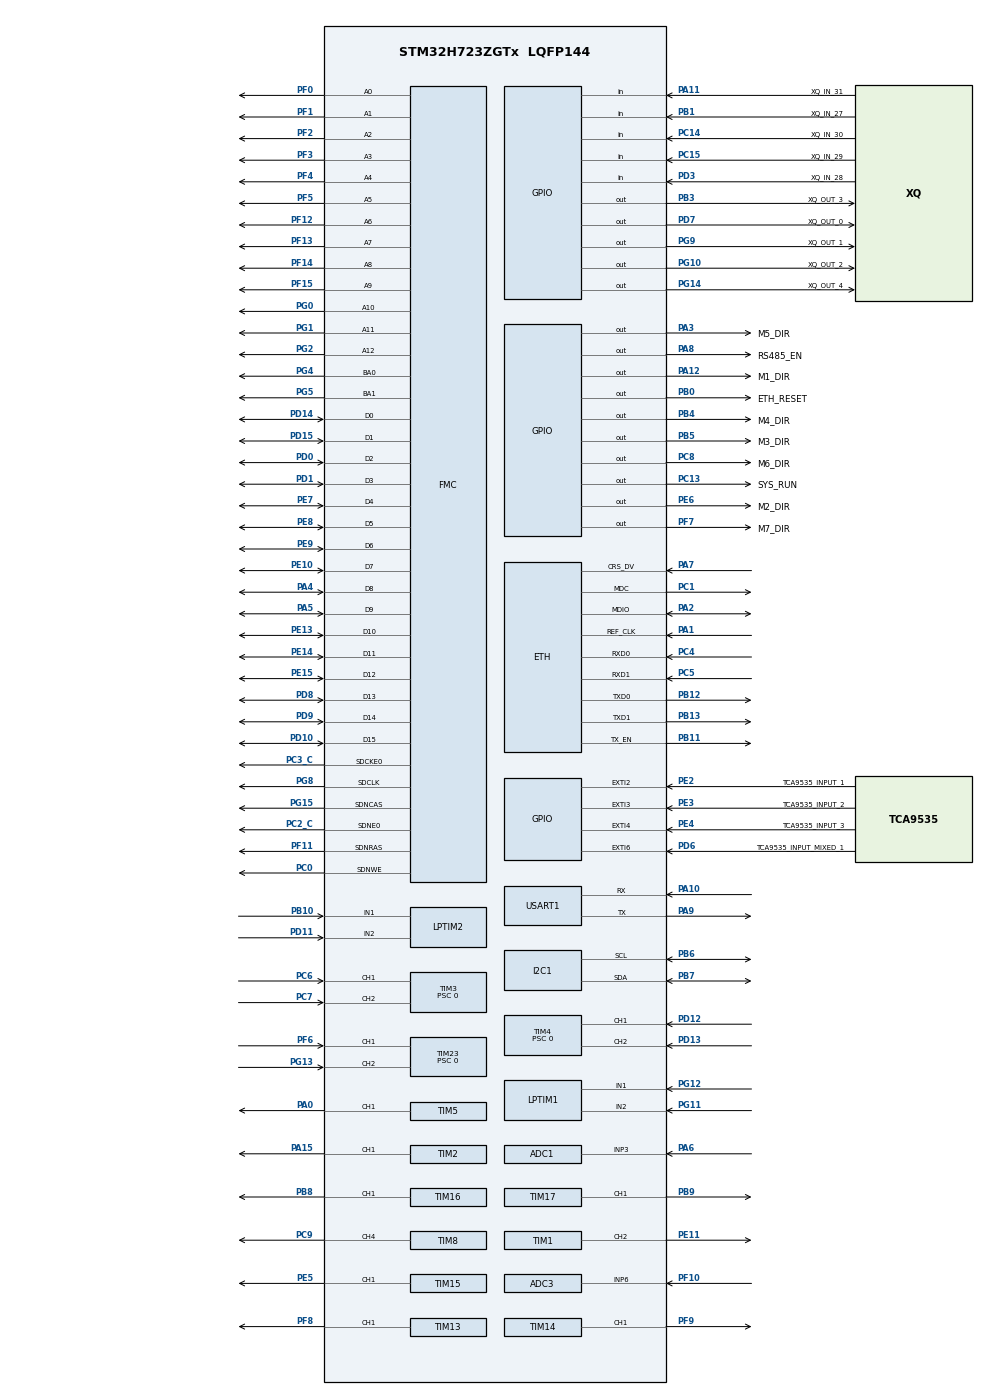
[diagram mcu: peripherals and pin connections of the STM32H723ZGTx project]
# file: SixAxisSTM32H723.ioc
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ADC1.Channel-1\#ChannelRegularConversion=ADC_CHANNEL_3
ADC1.ClockPrescaler=ADC_CLOCK_ASYNC_DIV2
ADC1.ClockPrescalerADC3=ADC_CLOCK_ASYNC_DIV2
ADC1.ContinuousConvMode=ENABLE
ADC1.ConversionDataManagement=ADC_CONVERSIONDATA_DMA_CIRCULAR
ADC1.DMAAccessModeView=ENABLE
ADC1.ExternalTrigConv=ADC_SOFTWARE_START
ADC1.Mode=ADC_DUALMODE_INTERL
ADC1.NbrOfConversion=1
ADC1.NbrOfConversionFlag=1
ADC1.OffsetNumber-1\#ChannelRegularConversion=ADC_OFFSET_NONE
ADC1.OffsetSignedSaturation-1\#ChannelRegularConversion=DISABLE
ADC1.Overrun=ADC_OVR_DATA_OVERWRITTEN
ADC1.Rank-1\#ChannelRegularConversion=1
ADC1.Resolution=ADC_RESOLUTION_14B
ADC1.SamplingTime-1\#ChannelRegularConversion=ADC_SAMPLETIME_2CYCLES_5
ADC1.TwoSamplingDelay=ADC_TWOSAMPLINGDELAY_2CYCLES
ADC1.master=1
ADC2.Channel-1\#ChannelRegularConversion=ADC_CHANNEL_3
ADC2.ClockPrescaler=ADC_CLOCK_ASYNC_DIV2
ADC2.ClockPrescalerADC3=ADC_CLOCK_ASYNC_DIV2
ADC2.DMAAccessModeView=ENABLE
ADC2.Mode=ADC_DUALMODE_INTERL
ADC2.NbrOfConversionFlag=1
ADC2.OffsetNumber-1\#ChannelRegularConversion=ADC_OFFSET_NONE
ADC2.OffsetSignedSaturation-1\#ChannelRegularConversion=DISABLE
ADC2.Rank-1\#ChannelRegularConversion=1
ADC2.Resolution=ADC_RESOLUTION_14B
ADC2.SamplingTime-1\#ChannelRegularConversion=ADC_SAMPLETIME_2CYCLES_5
ADC2.TwoSamplingDelay=ADC_TWOSAMPLINGDELAY_2CYCLES
ADC3.Channel-3\#ChannelRegularConversion=ADC_CHANNEL_6
ADC3.ClockPrescaler=ADC_CLOCK_ASYNC_DIV2
ADC3.ClockPrescalerADC3=ADC_CLOCK_ASYNC_DIV2
ADC3.ContinuousConvMode=DISABLE
ADC3.ConversionDataManagement=ADC_CONVERSIONDATA_DMA_CIRCULAR
ADC3.DMAAccessModeView=ENABLE
ADC3.DMAContinuousRequests=ENABLE
ADC3.ExternalTrigConv=ADC_EXTERNALTRIG_T6_TRGO
ADC3.Mode=ADC_DUALMODE_INTERL
ADC3.NbrOfConversion=1
ADC3.NbrOfConversionFlag=1
ADC3.OffsetNumber-3\#ChannelRegularConversion=ADC_OFFSET_NONE
ADC3.OffsetSign-3\#ChannelRegularConversion=ADC3_OFFSET_SIGN_NEGATIVE
ADC3.Overrun=ADC_OVR_DATA_OVERWRITTEN
ADC3.Rank-3\#ChannelRegularConversion=1
ADC3.SamplingTime-3\#ChannelRegularConversion=ADC3_SAMPLETIME_2CYCLES_5
ADC3.TwoSamplingDelay=ADC_TWOSAMPLINGDELAY_2CYCLES
CORTEX_M7.AccessPermission_S-Cortex_Memory_Protection_Unit_Region1_Settings_S=MPU_REGION_FULL_ACCESS
CORTEX_M7.AccessPermission_S-Cortex_Memory_Protection_Unit_Region2_Settings_S=MPU_REGION_FULL_ACCESS
CORTEX_M7.AccessPermission_S-Cortex_Memory_Protection_Unit_Region3_Settings_S=MPU_REGION_FULL_ACCESS
CORTEX_M7.AccessPermission_S-Cortex_Memory_Protection_Unit_Region4_Settings_S=MPU_REGION_FULL_ACCESS
CORTEX_M7.BaseAddress_S-Cortex_Memory_Protection_Unit_Region1_Settings_S=0x30000000
CORTEX_M7.BaseAddress_S-Cortex_Memory_Protection_Unit_Region2_Settings_S=0x30004000
CORTEX_M7.BaseAddress_S-Cortex_Memory_Protection_Unit_Region3_Settings_S=0x38000000
CORTEX_M7.BaseAddress_S-Cortex_Memory_Protection_Unit_Region4_Settings_S=0xC0000000
CORTEX_M7.CPU_DCache=Enabled
CORTEX_M7.CPU_ICache=Enabled
CORTEX_M7.DisableExec_S-Cortex_Memory_Protection_Unit_Region1_Settings_S=MPU_INSTRUCTION_ACCESS_DISABLE
CORTEX_M7.DisableExec_S-Cortex_Memory_Protection_Unit_Region2_Settings_S=MPU_INSTRUCTION_ACCESS_DISABLE
CORTEX_M7.DisableExec_S-Cortex_Memory_Protection_Unit_Region3_Settings_S=MPU_INSTRUCTION_ACCESS_ENABLE
CORTEX_M7.Enable_S-Cortex_Memory_Protection_Unit_Region1_Settings_S=MPU_REGION_ENABLE
CORTEX_M7.Enable_S-Cortex_Memory_Protection_Unit_Region2_Settings_S=MPU_REGION_ENABLE
CORTEX_M7.Enable_S-Cortex_Memory_Protection_Unit_Region3_Settings_S=MPU_REGION_ENABLE
CORTEX_M7.Enable_S-Cortex_Memory_Protection_Unit_Region4_Settings_S=MPU_REGION_ENABLE
CORTEX_M7.IsBufferable_S-Cortex_Memory_Protection_Unit_Region1_Settings_S=MPU_ACCESS_BUFFERABLE
CORTEX_M7.IsBufferable_S-Cortex_Memory_Protection_Unit_Region3_Settings_S=MPU_ACCESS_BUFFERABLE
CORTEX_M7.IsBufferable_S-Cortex_Memory_Protection_Unit_Region4_Settings_S=MPU_ACCESS_BUFFERABLE
CORTEX_M7.IsCacheable_S-Cortex_Memory_Protection_Unit_Region3_Settings_S=MPU_ACCESS_CACHEABLE
CORTEX_M7.IsCacheable_S-Cortex_Memory_Protection_Unit_Region4_Settings_S=MPU_ACCESS_CACHEABLE
CORTEX_M7.IsShareable_S-Cortex_Memory_Protection_Unit_Region3_Settings_S=MPU_ACCESS_SHAREABLE
CORTEX_M7.IsShareable_Spec=MPU_ACCESS_NOT_SHAREABLE
CORTEX_M7.Size_S-Cortex_Memory_Protection_Unit_Region1_Settings_S=MPU_REGION_SIZE_16KB
CORTEX_M7.Size_S-Cortex_Memory_Protection_Unit_Region2_Settings_S=MPU_REGION_SIZE_16KB
CORTEX_M7.Size_S-Cortex_Memory_Protection_Unit_Region3_Settings_S=MPU_REGION_SIZE_16KB
CORTEX_M7.Size_S-Cortex_Memory_Protection_Unit_Region4_Settings_S=MPU_REGION_SIZE_256MB
CORTEX_M7.TypeExtField_S-Cortex_Memory_Protection_Unit_Region1_Settings_S=MPU_TEX_LEVEL1
CORTEX_M7.TypeExtField_S-Cortex_Memory_Protection_Unit_Region2_Settings_S=MPU_TEX_LEVEL1
CORTEX_M7.TypeExtField_S-Cortex_Memory_Protection_Unit_Region3_Settings_S=MPU_TEX_LEVEL1
CORTEX_M7.default_mode_Activation=1
Dma.ADC1.0.Direction=DMA_PERIPH_TO_MEMORY
Dma.ADC1.0.EventEnable=DISABLE
Dma.ADC1.0.FIFOMode=DMA_FIFOMODE_DISABLE
Dma.ADC1.0.Instance=DMA1_Stream1
Dma.ADC1.0.MemDataAlignment=DMA_MDATAALIGN_WORD
Dma.ADC1.0.MemInc=DMA_MINC_ENABLE
Dma.ADC1.0.Mode=DMA_CIRCULAR
Dma.ADC1.0.PeriphDataAlignment=DMA_PDATAALIGN_WORD
Dma.ADC1.0.PeriphInc=DMA_PINC_DISABLE
Dma.ADC1.0.Polarity=HAL_DMAMUX_REQ_GEN_RISING
Dma.ADC1.0.Priority=DMA_PRIORITY_LOW
Dma.ADC1.0.RequestNumber=1
Dma.ADC1.0.SignalID=NONE
Dma.ADC1.0.SyncEnable=DISABLE
Dma.ADC1.0.SyncPolarity=HAL_DMAMUX_SYNC_NO_EVENT
Dma.ADC1.0.SyncRequestNumber=1
Dma.ADC1.0.SyncSignalID=NONE
Dma.ADC3.1.Direction=DMA_PERIPH_TO_MEMORY
Dma.ADC3.1.EventEnable=DISABLE
Dma.ADC3.1.FIFOMode=DMA_FIFOMODE_DISABLE
Dma.ADC3.1.Instance=DMA1_Stream2
Dma.ADC3.1.MemDataAlignment=DMA_MDATAALIGN_HALFWORD
Dma.ADC3.1.MemInc=DMA_MINC_ENABLE
Dma.ADC3.1.Mode=DMA_CIRCULAR
Dma.ADC3.1.PeriphDataAlignment=DMA_PDATAALIGN_HALFWORD
Dma.ADC3.1.PeriphInc=DMA_PINC_DISABLE
Dma.ADC3.1.Polarity=HAL_DMAMUX_REQ_GEN_RISING
Dma.ADC3.1.Priority=DMA_PRIORITY_LOW
Dma.ADC3.1.RequestNumber=1
Dma.ADC3.1.SignalID=NONE
Dma.ADC3.1.SyncEnable=DISABLE
Dma.ADC3.1.SyncPolarity=HAL_DMAMUX_SYNC_NO_EVENT
Dma.ADC3.1.SyncRequestNumber=1
Dma.ADC3.1.SyncSignalID=NONE
Dma.Request0=ADC1
Dma.Request1=ADC3
ETH.MediaInterface=HAL_ETH_RMII_MODE
FMC.CASLatency1=FMC_SDRAM_CAS_LATENCY_3
FMC.ColumnBitsNumber1=FMC_SDRAM_COLUMN_BITS_NUM_9
FMC.ExitSelfRefreshDelay1=8
FMC.LoadToActiveDelay1=3
FMC.RCDDelay1=2
FMC.RPDelay1=2
FMC.RPDelay2=2
FMC.ReadBurst1=FMC_SDRAM_RBURST_ENABLE
FMC.ReadBurst2=FMC_SDRAM_RBURST_ENABLE
FMC.ReadPipeDelay1=FMC_SDRAM_RPIPE_DELAY_1
FMC.ReadPipeDelay2=FMC_SDRAM_RPIPE_DELAY_1
FMC.RowCycleDelay1=7
FMC.RowCycleDelay2=7
FMC.SDClockPeriod1=FMC_SDRAM_CLOCK_PERIOD_2
FMC.SDClockPeriod2=FMC_SDRAM_CLOCK_PERIOD_2
FMC.SelfRefreshTime1=5
FMC.WriteRecoveryTime1=3
FREERTOS.Tasks01=defaultTask,24,512,StartDefaultTask,Default,NULL,Dynamic,NULL,NULL
FREERTOS.configQUEUE_REGISTRY_SIZE=32
FREERTOS.configTOTAL_HEAP_SIZE=131072
I2C1.Timing=0x20A0A3F6
LPTIM1.ULPClockPolarity=LPTIM_CLOCKPOLARITY_RISING_FALLING
LPTIM2.ULPClockPolarity=LPTIM_CLOCKPOLARITY_RISING_FALLING
LWIP.BSP.number=1
LWIP.GATEWAY_ADDRESS=192.168.010.001
LWIP.IP_ADDRESS=192.168.010.012
LWIP.LWIP_DHCP=0
LWIP.LWIP_SO_RCVTIMEO=1
LWIP.MEM_SIZE=15360
LWIP.NETMASK_ADDRESS=255.255.255.000
LWIP.Version=v2.2.1_Cube
LWIP0.BSP.STBoard=false
LWIP0.BSP.api=BSP_COMPONENT_DRIVER
LWIP0.BSP.component=LAN8742
LWIP0.BSP.instance=LAN8742
LWIP0.BSP.name=Driver_PHY
LWIP0.BSP.semaphore=S_LAN8742
LWIP0.BSP.solution=LAN8742
Mcu.Family=STM32H7
Mcu.Name=STM32H723ZGTx
Mcu.Package=LQFP144
NVIC.ADC3_IRQn=true\:5\:0\:false\:false\:true\:true\:true\:true\:true
NVIC.ADC_IRQn=true\:5\:0\:false\:false\:true\:true\:true\:true\:true
NVIC.DMA1_Stream1_IRQn=true\:5\:0\:false\:false\:true\:false\:false\:true\:true
NVIC.DMA1_Stream2_IRQn=true\:5\:0\:false\:false\:true\:false\:false\:true\:true
NVIC.ETH_IRQn=true\:5\:0\:false\:false\:true\:true\:true\:true\:true
NVIC.PriorityGroup=NVIC_PRIORITYGROUP_4
NVIC.TIM8_BRK_TIM12_IRQn=true\:15\:0\:false\:false\:true\:false\:false\:true\:true
NVIC.TimeBase=TIM8_BRK_TIM12_IRQn
NVIC.TimeBaseIP=TIM12
PA0.Signal=S_TIM5_CH1
PA1.GPIO_Speed=GPIO_SPEED_FREQ_VERY_HIGH
PA1.Mode=RMII
PA1.Signal=ETH_REF_CLK
PA10.Mode=Asynchronous
PA10.Signal=USART1_RX
PA11.GPIO_Label=XQ_IN_31
PA11.GPIO_PuPd=GPIO_PULLDOWN
PA11.Signal=GPIO_Input
PA12.GPIO_Label=M1_DIR
PA12.GPIO_Speed=GPIO_SPEED_FREQ_VERY_HIGH
PA12.Signal=GPIO_Output
PA15(JTDI).GPIO_PuPd=GPIO_PULLDOWN
PA15(JTDI).GPIO_Speed=GPIO_SPEED_FREQ_VERY_HIGH
PA15(JTDI).Signal=S_TIM2_CH1_ETR
PA2.GPIO_Speed=GPIO_SPEED_FREQ_VERY_HIGH
PA2.Mode=RMII
PA2.Signal=ETH_MDIO
PA3.GPIO_Label=M5_DIR
PA3.GPIO_Speed=GPIO_SPEED_FREQ_VERY_HIGH
PA3.Signal=GPIO_Output
PA4.Signal=FMC_D8_DA8
PA5.Signal=FMC_D9_DA9
PA6.Signal=ADCx_INP3
PA7.GPIO_Speed=GPIO_SPEED_FREQ_VERY_HIGH
PA7.Mode=RMII
PA7.Signal=ETH_CRS_DV
PA8.GPIO_Label=RS485_EN
PA8.GPIO_Speed=GPIO_SPEED_FREQ_VERY_HIGH
PA8.PinState=GPIO_PIN_SET
PA8.Signal=GPIO_Output
PA9.Mode=Asynchronous
PA9.Signal=USART1_TX
PB0.GPIO_Label=ETH_RESET
PB0.GPIO_Speed=GPIO_SPEED_FREQ_VERY_HIGH
PB0.PinState=GPIO_PIN_SET
PB0.Signal=GPIO_Output
PB1.GPIO_Label=XQ_IN_27
PB1.GPIO_PuPd=GPIO_PULLDOWN
PB1.Signal=GPIO_Input
PB10.Mode=Encoder_mode_occur1
PB10.Signal=LPTIM2_IN1
PB11.GPIO_Speed=GPIO_SPEED_FREQ_VERY_HIGH
PB11.Mode=RMII
PB11.Signal=ETH_TX_EN
PB12.GPIO_Speed=GPIO_SPEED_FREQ_VERY_HIGH
PB12.Mode=RMII
PB12.Signal=ETH_TXD0
PB13.GPIO_Speed=GPIO_SPEED_FREQ_VERY_HIGH
PB13.Mode=RMII
PB13.Signal=ETH_TXD1
PB3(JTDO/TRACESWO).GPIO_Label=XQ_OUT_3
PB3(JTDO/TRACESWO).PinState=GPIO_PIN_SET
PB3(JTDO/TRACESWO).Signal=GPIO_Output
PB4(NJTRST).GPIO_Label=M4_DIR
PB4(NJTRST).GPIO_Speed=GPIO_SPEED_FREQ_VERY_HIGH
PB4(NJTRST).Signal=GPIO_Output
PB5.GPIO_Label=M3_DIR
PB5.GPIO_Speed=GPIO_SPEED_FREQ_VERY_HIGH
PB5.Signal=GPIO_Output
PB6.Mode=I2C
PB6.Signal=I2C1_SCL
PB7.Mode=I2C
PB7.Signal=I2C1_SDA
PB8.GPIO_PuPd=GPIO_PULLDOWN
PB8.GPIO_Speed=GPIO_SPEED_FREQ_VERY_HIGH
PB8.Signal=S_TIM16_CH1
PB9.GPIO_PuPd=GPIO_PULLDOWN
PB9.GPIO_Speed=GPIO_SPEED_FREQ_VERY_HIGH
PB9.Signal=S_TIM17_CH1
PC0.Signal=FMC_SDNWE
PC1.GPIO_Speed=GPIO_SPEED_FREQ_VERY_HIGH
PC1.Mode=RMII
PC1.Signal=ETH_MDC
PC13.GPIO_Label=SYS_RUN
PC13.Signal=GPIO_Output
PC14-OSC32_IN.GPIO_Label=XQ_IN_30
PC14-OSC32_IN.GPIO_PuPd=GPIO_PULLDOWN
PC14-OSC32_IN.Signal=GPIO_Input
PC15-OSC32_OUT.GPIO_Label=XQ_IN_29
PC15-OSC32_OUT.GPIO_PuPd=GPIO_PULLDOWN
PC15-OSC32_OUT.Signal=GPIO_Input
PC2_C.Mode=SdramChipSelect1_1
PC2_C.Signal=FMC_SDNE0
PC3_C.Mode=SdramChipSelect1_1
PC3_C.Signal=FMC_SDCKE0
PC4.GPIO_Speed=GPIO_SPEED_FREQ_VERY_HIGH
PC4.Mode=RMII
PC4.Signal=ETH_RXD0
PC5.GPIO_Speed=GPIO_SPEED_FREQ_VERY_HIGH
PC5.Mode=RMII
PC5.Signal=ETH_RXD1
PC6.Signal=S_TIM3_CH1
PC7.Signal=S_TIM3_CH2
PC8.GPIO_Label=M6_DIR
PC8.GPIO_Speed=GPIO_SPEED_FREQ_VERY_HIGH
PC8.Signal=GPIO_Output
PC9.Signal=S_TIM8_CH4
PD0.Signal=FMC_D2_DA2
PD1.Signal=FMC_D3_DA3
PD10.Signal=FMC_D15_DA15
PD11.Mode=Encoder_mode_occur1
PD11.Signal=LPTIM2_IN2
PD12.GPIO_Speed=GPIO_SPEED_FREQ_VERY_HIGH
PD12.Signal=S_TIM4_CH1
PD13.GPIO_Speed=GPIO_SPEED_FREQ_VERY_HIGH
PD13.Signal=S_TIM4_CH2
PD14.Signal=FMC_D0_DA0
PD15.Signal=FMC_D1_DA1
PD3.GPIO_Label=XQ_IN_28
PD3.GPIO_PuPd=GPIO_PULLDOWN
PD3.Signal=GPIO_Input
PD6.GPIO_Label=TCA9535_INPUT_MIXED_1
PD6.GPIO_ModeDefaultEXTI=GPIO_MODE_IT_FALLING
PD6.Signal=GPXTI6
PD7.GPIO_Label=XQ_OUT_0
PD7.PinState=GPIO_PIN_SET
PD7.Signal=GPIO_Output
PD8.Signal=FMC_D13_DA13
PD9.Signal=FMC_D14_DA14
PE10.Signal=FMC_D7_DA7
PE11.Signal=S_TIM1_CH2
PE13.Signal=FMC_D10_DA10
PE14.Signal=FMC_D11_DA11
PE15.Signal=FMC_D12_DA12
PE2.GPIO_Label=TCA9535_INPUT_1
PE2.GPIO_ModeDefaultEXTI=GPIO_MODE_IT_FALLING
PE2.Signal=GPXTI2
PE3.GPIO_Label=TCA9535_INPUT_2
PE3.GPIO_ModeDefaultEXTI=GPIO_MODE_IT_FALLING
PE3.Signal=GPXTI3
PE4.GPIO_Label=TCA9535_INPUT_3
PE4.GPIO_ModeDefaultEXTI=GPIO_MODE_IT_FALLING
PE4.Signal=GPXTI4
PE5.GPIO_PuPd=GPIO_PULLDOWN
PE5.GPIO_Speed=GPIO_SPEED_FREQ_VERY_HIGH
PE5.Signal=S_TIM15_CH1
PE6.GPIO_Label=M2_DIR
PE6.GPIO_Speed=GPIO_SPEED_FREQ_VERY_HIGH
PE6.Signal=GPIO_Output
PE7.Signal=FMC_D4_DA4
PE8.Signal=FMC_D5_DA5
PE9.Signal=FMC_D6_DA6
PF0.Signal=FMC_A0
PF1.Signal=FMC_A1
PF10.Mode=IN6-Single-Ended
PF10.Signal=ADC3_INP6
PF11.Signal=FMC_SDNRAS
PF12.Signal=FMC_A6
PF13.Signal=FMC_A7
PF14.Signal=FMC_A8
PF15.Signal=FMC_A9
PF2.Signal=FMC_A2
PF3.Signal=FMC_A3
PF4.Signal=FMC_A4
PF5.Signal=FMC_A5
PF6.Mode=Encoder_Interface
PF6.Signal=TIM23_CH1
PF7.GPIO_Label=M7_DIR
PF7.GPIO_Speed=GPIO_SPEED_FREQ_VERY_HIGH
PF7.Signal=GPIO_Output
PF8.Signal=S_TIM13_CH1
PF9.Signal=S_TIM14_CH1
PG0.Signal=FMC_A10
PG1.Signal=FMC_A11
PG10.GPIO_Label=XQ_OUT_2
PG10.PinState=GPIO_PIN_SET
PG10.Signal=GPIO_Output
PG11.Mode=Encoder_mode_occur1
PG11.Signal=LPTIM1_IN2
PG12.Mode=Encoder_mode_occur1
PG12.Signal=LPTIM1_IN1
PG13.Signal=S_TIM23_CH2
PG14.GPIO_Label=XQ_OUT_4
PG14.PinState=GPIO_PIN_SET
PG14.Signal=GPIO_Output
PG15.Signal=FMC_SDNCAS
PG2.Signal=FMC_A12
PG4.Signal=FMC_A14_BA0
PG5.Signal=FMC_A15_BA1
PG8.Signal=FMC_SDCLK
PG9.GPIO_Label=XQ_OUT_1
PG9.PinState=GPIO_PIN_SET
PG9.Signal=GPIO_Output
PH0-OSC_IN.Mode=HSE-External-Oscillator
PH0-OSC_IN.Signal=RCC_OSC_IN
PH1-OSC_OUT.Mode=HSE-External-Oscillator
PH1-OSC_OUT.Signal=RCC_OSC_OUT
ProjectManager.HeapSize=0x200
ProjectManager.StackSize=0x400
ProjectManager.TargetToolchain=MDK-ARM V5.32
RCC.ADCFreq_Value=100000000
RCC.APB1Freq_Value=125000000
RCC.APB2Freq_Value=125000000
RCC.APB3Freq_Value=125000000
RCC.APB4Freq_Value=125000000
RCC.CortexFreq_Value=500000000
RCC.D1PPRE=RCC_APB3_DIV2
RCC.D2PPRE1=RCC_APB1_DIV2
RCC.D2PPRE2=RCC_APB2_DIV2
RCC.D3PPRE=RCC_APB4_DIV2
RCC.DIVM1=2
RCC.DIVM2=2
RCC.DIVN1=40
RCC.DIVN2=16
RCC.DIVP1=1
RCC.HCLKFreq_Value=250000000
RCC.HPRE=RCC_HCLK_DIV2
RCC.LPTIM1CLockSelection=RCC_LPTIM1CLKSOURCE_PLL2
RCC.LPTIM2CLockSelection=RCC_LPTIM2CLKSOURCE_PLL2
RCC.PLL2FRACN=0
RCC.PLL3_VCI_Range-AdvancedSettings=RCC_PLL3VCIRANGE_0
RCC.PLLFRACN=0
RCC.PLLSourceVirtual=RCC_PLLSOURCE_HSE
RCC.SYSCLKFreq_VALUE=500000000
RCC.SYSCLKSource=RCC_SYSCLKSOURCE_PLLCLK
RCC.USBFreq_Value=250000000
SH.ADCx_INP3.0=ADC1_INP3,IN3-Single-Ended
SH.ADCx_INP3.1=ADC2_INP3,IN3-Single-Ended
SH.FMC_A0.0=FMC_A0,13b-sda1
SH.FMC_A1.0=FMC_A1,13b-sda1
SH.FMC_A10.0=FMC_A10,13b-sda1
SH.FMC_A11.0=FMC_A11,13b-sda1
SH.FMC_A12.0=FMC_A12,13b-sda1
SH.FMC_A14_BA0.0=FMC_BA0,FourSdramBanks1
SH.FMC_A15_BA1.0=FMC_BA1,FourSdramBanks1
SH.FMC_A2.0=FMC_A2,13b-sda1
SH.FMC_A3.0=FMC_A3,13b-sda1
SH.FMC_A4.0=FMC_A4,13b-sda1
SH.FMC_A5.0=FMC_A5,13b-sda1
SH.FMC_A6.0=FMC_A6,13b-sda1
SH.FMC_A7.0=FMC_A7,13b-sda1
SH.FMC_A8.0=FMC_A8,13b-sda1
SH.FMC_A9.0=FMC_A9,13b-sda1
SH.FMC_D0_DA0.0=FMC_D0,sd-16b-d1
SH.FMC_D10_DA10.0=FMC_D10,sd-16b-d1
SH.FMC_D11_DA11.0=FMC_D11,sd-16b-d1
SH.FMC_D12_DA12.0=FMC_D12,sd-16b-d1
SH.FMC_D13_DA13.0=FMC_D13,sd-16b-d1
SH.FMC_D14_DA14.0=FMC_D14,sd-16b-d1
SH.FMC_D15_DA15.0=FMC_D15,sd-16b-d1
SH.FMC_D1_DA1.0=FMC_D1,sd-16b-d1
SH.FMC_D2_DA2.0=FMC_D2,sd-16b-d1
SH.FMC_D3_DA3.0=FMC_D3,sd-16b-d1
SH.FMC_D4_DA4.0=FMC_D4,sd-16b-d1
SH.FMC_D5_DA5.0=FMC_D5,sd-16b-d1
SH.FMC_D6_DA6.0=FMC_D6,sd-16b-d1
SH.FMC_D7_DA7.0=FMC_D7,sd-16b-d1
SH.FMC_D8_DA8.0=FMC_D8,sd-16b-d1
SH.FMC_D9_DA9.0=FMC_D9,sd-16b-d1
SH.FMC_SDCLK.0=FMC_SDCLK,13b-sda1
SH.FMC_SDNCAS.0=FMC_SDNCAS,13b-sda1
SH.FMC_SDNRAS.0=FMC_SDNRAS,13b-sda1
SH.FMC_SDNWE.0=FMC_SDNWE,13b-sda1
SH.S_TIM13_CH1.0=TIM13_CH1,PWM Generation1 CH1
SH.S_TIM14_CH1.0=TIM14_CH1,PWM Generation1 CH1
SH.S_TIM15_CH1.0=TIM15_CH1,PWM Generation1 CH1
SH.S_TIM16_CH1.0=TIM16_CH1,PWM Generation1 CH1
SH.S_TIM17_CH1.0=TIM17_CH1,PWM Generation1 CH1
SH.S_TIM1_CH2.0=TIM1_CH2,PWM Generation2 CH2
SH.S_TIM23_CH2.0=TIM23_CH2,Encoder_Interface
SH.S_TIM2_CH1_ETR.0=TIM2_CH1,PWM Generation1 CH1
SH.S_TIM3_CH1.0=TIM3_CH1,Encoder_Interface
SH.S_TIM3_CH2.0=TIM3_CH2,Encoder_Interface
SH.S_TIM4_CH1.0=TIM4_CH1,Encoder_Interface
SH.S_TIM4_CH2.0=TIM4_CH2,Encoder_Interface
SH.S_TIM5_CH1.0=TIM5_CH1,PWM Generation1 CH1
SH.S_TIM8_CH4.0=TIM8_CH4,PWM Generation4 CH4
TIM1.AutoReloadPreload=TIM_AUTORELOAD_PRELOAD_ENABLE
TIM1.Channel-PWM\ Generation2\ CH2=TIM_CHANNEL_2
TIM1.Prescaler=24
TIM13.AutoReloadPreload=TIM_AUTORELOAD_PRELOAD_ENABLE
TIM13.Channel=TIM_CHANNEL_1
TIM13.Prescaler=24
TIM14.AutoReloadPreload=TIM_AUTORELOAD_PRELOAD_ENABLE
TIM14.Channel=TIM_CHANNEL_1
TIM14.OCMode_PWM=TIM_OCMODE_PWM1
TIM14.Prescaler=24
TIM15.AutoReloadPreload=TIM_AUTORELOAD_PRELOAD_ENABLE
TIM15.Channel-PWM\ Generation1\ CH1=TIM_CHANNEL_1
TIM15.OCMode_PWM-PWM\ Generation1\ CH1=TIM_OCMODE_PWM1
TIM15.Prescaler=24
TIM16.AutoReloadPreload=TIM_AUTORELOAD_PRELOAD_ENABLE
TIM16.Channel=TIM_CHANNEL_1
TIM16.OCMode_PWM=TIM_OCMODE_PWM1
TIM16.Prescaler=24
TIM17.AutoReloadPreload=TIM_AUTORELOAD_PRELOAD_ENABLE
TIM17.Channel=TIM_CHANNEL_1
TIM17.OCMode_PWM=TIM_OCMODE_PWM1
TIM17.Prescaler=24
TIM2.AutoReloadPreload=TIM_AUTORELOAD_PRELOAD_ENABLE
TIM2.Channel-PWM\ Generation1\ CH1=TIM_CHANNEL_1
TIM2.OCMode_PWM-PWM\ Generation1\ CH1=TIM_OCMODE_PWM1
TIM2.Period=65535
TIM2.Prescaler=24
TIM2.Pulse-PWM\ Generation1\ CH1=500000
TIM23.AutoReloadPreload=TIM_AUTORELOAD_PRELOAD_ENABLE
TIM23.EncoderMode=TIM_ENCODERMODE_TI12
TIM23.Period=59999
TIM23.Prescaler=0
TIM3.AutoReloadPreload=TIM_AUTORELOAD_PRELOAD_ENABLE
TIM3.EncoderMode=TIM_ENCODERMODE_TI12
TIM3.Period=59999
TIM3.Prescaler=0
TIM4.AutoReloadPreload=TIM_AUTORELOAD_PRELOAD_ENABLE
TIM4.EncoderMode=TIM_ENCODERMODE_TI12
TIM4.IC1Filter=0
TIM4.IC2Filter=0
TIM4.Period=59999
TIM4.Prescaler=0
TIM5.AutoReloadPreload=TIM_AUTORELOAD_PRELOAD_ENABLE
TIM5.Channel-PWM\ Generation1\ CH1=TIM_CHANNEL_1
TIM5.Prescaler=24
TIM6.AutoReloadPreload=TIM_AUTORELOAD_PRELOAD_ENABLE
TIM6.Period=99
TIM6.Prescaler=0
TIM6.TIM_MasterOutputTrigger=TIM_TRGO_UPDATE
TIM7.AutoReloadPreload=TIM_AUTORELOAD_PRELOAD_ENABLE
TIM7.Prescaler=24
TIM8.AutoReloadPreload=TIM_AUTORELOAD_PRELOAD_ENABLE
TIM8.Channel-PWM\ Generation4\ CH4=TIM_CHANNEL_4
TIM8.OCMode_PWM-PWM\ Generation4\ CH4=TIM_OCMODE_PWM1
TIM8.Prescaler=24
USART1.VirtualMode-Asynchronous=VM_ASYNC
VP_FREERTOS_VS_CMSIS_V2.Mode=CMSIS_V2
VP_LWIP_VS_Enabled.Mode=Enabled
VP_MEMORYMAP_VS_MEMORYMAP.Mode=CurAppReg
VP_SYS_VS_tim12.Mode=TIM12
VP_TIM13_VS_ClockSourceINT.Mode=Enable_Timer
VP_TIM14_VS_ClockSourceINT.Mode=Enable_Timer
VP_TIM15_VS_ClockSourceINT.Mode=Internal
VP_TIM16_VS_ClockSourceINT.Mode=Enable_Timer
VP_TIM17_VS_ClockSourceINT.Mode=Enable_Timer
VP_TIM1_VS_ClockSourceINT.Mode=Internal
VP_TIM2_VS_ClockSourceINT.Mode=Internal
VP_TIM5_VS_ClockSourceINT.Mode=Internal
VP_TIM6_VS_ClockSourceINT.Mode=Enable_Timer
VP_TIM7_VS_ClockSourceINT.Mode=Enable_Timer
VP_TIM8_VS_ClockSourceINT.Mode=Internal
board=custom

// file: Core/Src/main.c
/* USER CODE BEGIN Header */
/**
  ******************************************************************************
  * @file           : main.c
  * @brief          : Main program body
  ******************************************************************************
  * @attention
  *
  * Copyright (c) 2025 STMicroelectronics.
  * All rights reserved.
  *
  * This software is licensed under terms that can be found in the LICENSE file
  * in the root directory of this software component.
  * If no LICENSE file comes with this software, it is provided AS-IS.
  *
  ******************************************************************************
  */
/* USER CODE END Header */
#include "main.h"
#include "FreeRTOS.h"
#include "cmsis_os2.h"
#include "adc.h"
#include "dma.h"
#include "i2c.h"
#include "lptim.h"
#include "lwip.h"
#include "tim.h"
#include "usart.h"
#include "gpio.h"
#include "fmc.h"

/* USER CODE BEGIN Includes */
#include "xq_axis.h"
#include "xq_io.h"
#include "xq_encoder.h"
#include "xq_pwm.h"
#include "mb.h"
/* USER CODE END Includes */

void SystemClock_Config(void);
void PeriphCommonClock_Config(void);
static void MPU_Config(void);
void MX_FREERTOS_Init(void);

/* USER CODE BEGIN 0 */

uint32_t data_len = 512;
uint32_t dmabuffer[512];

/* USER CODE END 0 */

int main(void)
{

  /* MPU Configuration--------------------------------------------------------*/
  MPU_Config();

  /* Enable the CPU Cache */

  /* Enable I-Cache---------------------------------------------------------*/
  SCB_EnableICache();

  /* Enable D-Cache---------------------------------------------------------*/
  SCB_EnableDCache();

  /* MCU Configuration--------------------------------------------------------*/

  /* Reset of all peripherals, Initializes the Flash interface and the Systick. */
  HAL_Init();

  /* USER CODE BEGIN Init */

  // SCB->CACR|=1<<2;

  /* USER CODE END Init */

  /* Configure the system clock */
  SystemClock_Config();

  /* Configure the peripherals common clocks */
  PeriphCommonClock_Config();

  /* Initialize all configured peripherals */
  MX_GPIO_Init();
  MX_DMA_Init();
  MX_TIM2_Init();
  MX_TIM8_Init();
  MX_TIM14_Init();
  MX_TIM15_Init();
  MX_TIM16_Init();
  MX_TIM17_Init();
  MX_TIM23_Init();
  MX_LPTIM2_Init();
  MX_TIM3_Init();
  MX_TIM4_Init();
  MX_I2C1_Init();
  MX_TIM1_Init();
  MX_TIM5_Init();
  MX_ADC1_Init();
  MX_ADC3_Init();
  MX_TIM7_Init();
  MX_USART1_UART_Init();
  MX_TIM6_Init();
  MX_TIM13_Init();
  MX_LPTIM1_Init();
  MX_FMC_Init();
  MX_ADC2_Init();
  /* USER CODE BEGIN 2 */

  printf ("System initialized.\n");

  /* USER CODE END 2 */

  /* Init scheduler */
  osKernelInitialize();  /* Call init function for freertos objects (in cmsis_os2.c) */
  MX_FREERTOS_Init();

  /* Start scheduler */
  osKernelStart();

  /* We should never get here as control is now taken by the scheduler */

  /* Infinite loop */
  while (1)
  {

  }
}

void SystemClock_Config(void)
{
  RCC_OscInitTypeDef RCC_OscInitStruct = {0};
  RCC_ClkInitTypeDef RCC_ClkInitStruct = {0};

  /** Supply configuration update enable
  */
  HAL_PWREx_ConfigSupply(PWR_LDO_SUPPLY);

  /** Configure the main internal regulator output voltage
  */
  __HAL_PWR_VOLTAGESCALING_CONFIG(PWR_REGULATOR_VOLTAGE_SCALE0);

  while(!__HAL_PWR_GET_FLAG(PWR_FLAG_VOSRDY)) {}

  /** Initializes the RCC Oscillators according to the specified parameters
  * in the RCC_OscInitTypeDef structure.
  */
  RCC_OscInitStruct.OscillatorType = RCC_OSCILLATORTYPE_HSE;
  RCC_OscInitStruct.HSEState = RCC_HSE_ON;
  RCC_OscInitStruct.PLL.PLLState = RCC_PLL_ON;
  RCC_OscInitStruct.PLL.PLLSource = RCC_PLLSOURCE_HSE;
  RCC_OscInitStruct.PLL.PLLM = 2;
  RCC_OscInitStruct.PLL.PLLN = 40;
  RCC_OscInitStruct.PLL.PLLP = 1;
  RCC_OscInitStruct.PLL.PLLQ = 2;
  RCC_OscInitStruct.PLL.PLLR = 2;
  RCC_OscInitStruct.PLL.PLLRGE = RCC_PLL1VCIRANGE_3;
  RCC_OscInitStruct.PLL.PLLVCOSEL = RCC_PLL1VCOWIDE;
  RCC_OscInitStruct.PLL.PLLFRACN = 0;
  if (HAL_RCC_OscConfig(&RCC_OscInitStruct) != HAL_OK)
  {
    Error_Handler();
  }

  /** Initializes the CPU, AHB and APB buses clocks
  */
  RCC_ClkInitStruct.ClockType = RCC_CLOCKTYPE_HCLK|RCC_CLOCKTYPE_SYSCLK
                              |RCC_CLOCKTYPE_PCLK1|RCC_CLOCKTYPE_PCLK2
                              |RCC_CLOCKTYPE_D3PCLK1|RCC_CLOCKTYPE_D1PCLK1;
  RCC_ClkInitStruct.SYSCLKSource = RCC_SYSCLKSOURCE_PLLCLK;
  RCC_ClkInitStruct.SYSCLKDivider = RCC_SYSCLK_DIV1;
  RCC_ClkInitStruct.AHBCLKDivider = RCC_HCLK_DIV2;
  RCC_ClkInitStruct.APB3CLKDivider = RCC_APB3_DIV2;
  RCC_ClkInitStruct.APB1CLKDivider = RCC_APB1_DIV2;
  RCC_ClkInitStruct.APB2CLKDivider = RCC_APB2_DIV2;
  RCC_ClkInitStruct.APB4CLKDivider = RCC_APB4_DIV2;

  if (HAL_RCC_ClockConfig(&RCC_ClkInitStruct, FLASH_LATENCY_3) != HAL_OK)
  {
    Error_Handler();
  }
}

void PeriphCommonClock_Config(void)
{
  RCC_PeriphCLKInitTypeDef PeriphClkInitStruct = {0};

  /** Initializes the peripherals clock
  */
  PeriphClkInitStruct.PeriphClockSelection = RCC_PERIPHCLK_ADC|RCC_PERIPHCLK_LPTIM1
                              |RCC_PERIPHCLK_LPTIM2;
  PeriphClkInitStruct.PLL2.PLL2M = 2;
  PeriphClkInitStruct.PLL2.PLL2N = 16;
  PeriphClkInitStruct.PLL2.PLL2P = 2;
  PeriphClkInitStruct.PLL2.PLL2Q = 2;
  PeriphClkInitStruct.PLL2.PLL2R = 2;
  PeriphClkInitStruct.PLL2.PLL2RGE = RCC_PLL2VCIRANGE_3;
  PeriphClkInitStruct.PLL2.PLL2VCOSEL = RCC_PLL2VCOWIDE;
  PeriphClkInitStruct.PLL2.PLL2FRACN = 0;
  PeriphClkInitStruct.Lptim1ClockSelection = RCC_LPTIM1CLKSOURCE_PLL2;
  PeriphClkInitStruct.Lptim2ClockSelection = RCC_LPTIM2CLKSOURCE_PLL2;
  PeriphClkInitStruct.AdcClockSelection = RCC_ADCCLKSOURCE_PLL2;
  if (HAL_RCCEx_PeriphCLKConfig(&PeriphClkInitStruct) != HAL_OK)
  {
    Error_Handler();
  }
}

 /* MPU Configuration */

void MPU_Config(void)
{
  MPU_Region_InitTypeDef MPU_InitStruct = {0};

  /* Disables the MPU */
  HAL_MPU_Disable();

  /** Initializes and configures the Region and the memory to be protected
  */
  MPU_InitStruct.Enable = MPU_REGION_ENABLE;
  MPU_InitStruct.Number = MPU_REGION_NUMBER0;
  MPU_InitStruct.BaseAddress = 0x0;
  MPU_InitStruct.Size = MPU_REGION_SIZE_4GB;
  MPU_InitStruct.SubRegionDisable = 0x87;
  MPU_InitStruct.TypeExtField = MPU_TEX_LEVEL0;
  MPU_InitStruct.AccessPermission = MPU_REGION_NO_ACCESS;
  MPU_InitStruct.DisableExec = MPU_INSTRUCTION_ACCESS_DISABLE;
  MPU_InitStruct.IsShareable = MPU_ACCESS_NOT_SHAREABLE;
  MPU_InitStruct.IsCacheable = MPU_ACCESS_NOT_CACHEABLE;
  MPU_InitStruct.IsBufferable = MPU_ACCESS_NOT_BUFFERABLE;

  HAL_MPU_ConfigRegion(&MPU_InitStruct);

  /** Initializes and configures the Region and the memory to be protected
  */
  MPU_InitStruct.Number = MPU_REGION_NUMBER1;
  MPU_InitStruct.BaseAddress = 0x30000000;
  MPU_InitStruct.Size = MPU_REGION_SIZE_16KB;
  MPU_InitStruct.SubRegionDisable = 0x0;
  MPU_InitStruct.TypeExtField = MPU_TEX_LEVEL1;
  MPU_InitStruct.AccessPermission = MPU_REGION_FULL_ACCESS;
  MPU_InitStruct.IsBufferable = MPU_ACCESS_BUFFERABLE;

  HAL_MPU_ConfigRegion(&MPU_InitStruct);

  /** Initializes and configures the Region and the memory to be protected
  */
  MPU_InitStruct.Number = MPU_REGION_NUMBER2;
  MPU_InitStruct.BaseAddress = 0x30004000;
  MPU_InitStruct.IsBufferable = MPU_ACCESS_NOT_BUFFERABLE;

  HAL_MPU_ConfigRegion(&MPU_InitStruct);

  /** Initializes and configures the Region and the memory to be protected
  */
  MPU_InitStruct.Number = MPU_REGION_NUMBER3;
  MPU_InitStruct.BaseAddress = 0x38000000;
  MPU_InitStruct.DisableExec = MPU_INSTRUCTION_ACCESS_ENABLE;
  MPU_InitStruct.IsShareable = MPU_ACCESS_SHAREABLE;
  MPU_InitStruct.IsCacheable = MPU_ACCESS_CACHEABLE;
  MPU_InitStruct.IsBufferable = MPU_ACCESS_BUFFERABLE;

  HAL_MPU_ConfigRegion(&MPU_InitStruct);

  /** Initializes and configures the Region and the memory to be protected
  */
  MPU_InitStruct.Number = MPU_REGION_NUMBER4;
  MPU_InitStruct.BaseAddress = 0xC0000000;
  MPU_InitStruct.Size = MPU_REGION_SIZE_256MB;
  MPU_InitStruct.TypeExtField = MPU_TEX_LEVEL0;
  MPU_InitStruct.IsShareable = MPU_ACCESS_NOT_SHAREABLE;

  HAL_MPU_ConfigRegion(&MPU_InitStruct);
  /* Enables the MPU */
  HAL_MPU_Enable(MPU_PRIVILEGED_DEFAULT);

}

void HAL_TIM_PeriodElapsedCallback(TIM_HandleTypeDef *htim)
{
  /* USER CODE BEGIN Callback 0 */

  XQ_Encoder_TIM_Callback(htim);

  /* USER CODE END Callback 0 */
  if (htim->Instance == TIM12)
  {
    HAL_IncTick();
  }
}

void Error_Handler(void)
{
  __disable_irq();
  while (1)
  {
  }
}

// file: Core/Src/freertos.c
/* USER CODE BEGIN Header */
/**
  ******************************************************************************
  * File Name          : freertos.c
  * Description        : Code for freertos applications
  ******************************************************************************
  * @attention
  *
  * Copyright (c) 2025 STMicroelectronics.
  * All rights reserved.
  *
  * This software is licensed under terms that can be found in the LICENSE file
  * in the root directory of this software component.
  * If no LICENSE file comes with this software, it is provided AS-IS.
  *
  ******************************************************************************
  */
/* USER CODE END Header */

#include "FreeRTOS.h"
#include "task.h"
#include "main.h"
#include "FreeRTOS.h"
#include "cmsis_os2.h"

/* USER CODE BEGIN Includes */
#include "usart.h"
#include "string.h"
#include "xq_axis.h"
#include "ht_client_task.h"
#include "ht_udp_server.h"
#include "mb.h"
#include "adc.h"
#include "xq_io.h"
#include "xq_encoder.h"
#include "xq_adc.h"
#include "xq_period_task.h"
#include "xq_pwm.h"
#include "xq_dac.h"
#include "tim.h"
#include "xq_sdram.h"
#include "xq_axis_intp.h"
#include "xq_reg_event.h"
#include "xq_control.h"
/* USER CODE END Includes */

/* Definitions for defaultTask */
osThreadId_t defaultTaskHandle;
const osThreadAttr_t defaultTask_attributes = {
  .name = "defaultTask",
  .stack_size = 512 * 4,
  .priority = (osPriority_t) osPriorityNormal,
};

/* USER CODE BEGIN FunctionPrototypes */
void xq_control_task(void *pvParameters) {
    uint16_t addr;
    for (;;) {
        if (xQueueReceive(xq_reg_event_queue, &addr, portMAX_DELAY) == pdTRUE) {
            int index = addr - REG_ADDR_MIN;
            if (index >= 0 && index < REG_SLOT_COUNT) {
                RegEventHandler_t handler = xq_reg_handler_table[index];
                if (handler != NULL) {
                    handler(addr);   // 执行槽函数
                }
            }
        }
    }
}
/* USER CODE END FunctionPrototypes */

void StartDefaultTask(void *argument);

extern void MX_LWIP_Init(void);
void MX_FREERTOS_Init(void); /* (MISRA C 2004 rule 8.1) */

void MX_FREERTOS_Init(void) {

  /* Create the thread(s) */
  /* creation of defaultTask */
  defaultTaskHandle = osThreadNew(StartDefaultTask, NULL, &defaultTask_attributes);

}

/* USER CODE BEGIN Header_StartDefaultTask */

// uint8_t level[1000];
// float_t adc_voltage[1000];

/**
  * @brief  Function implementing the defaultTask thread.
  * @param  argument: Not used
  * @retval None
  */
/* USER CODE END Header_StartDefaultTask */
void StartDefaultTask(void *argument)
{
  /* init code for LWIP */
  MX_LWIP_Init();
  /* USER CODE BEGIN StartDefaultTask */

  xq_axis_init();

  ht_client_task_init();

  ht_udp_server_init();

  XQ_TCA9535_Init_All();

  XQ_PeriodTask_Start();

  XQ_Encoder_Start(1, -1, -1, -1, 1);

  xq_modbus_tcp_task_init ();

  xq_reg_event_init();               // 创建队列
  xq_register_all_handlers();        // 注册所有处理函数
  xTaskCreate(xq_control_task, "Ctrl", 512, NULL, osPriorityHigh, NULL);

  XQ_setPWM(0, 0.5, 10.0, 5, 100);
  XQ_setPWM(1, 0.5, 10.0, 5, 100);

  XQ_StartADC (ADC_CHANNEL_DUAL_MODE);
  XQ_StartADC (ADC_CHANNEL_ADC3);

  // 创建模拟刷新任务
  xTaskCreate(xq_Analog_Refresh_Task, "AnalogRfrsh", 512, NULL,
              osPriorityNormal, &xAnalogRefreshTaskHandle);

  // 初始化DAC (0-5V范围)
  XQ_DAC_Init(GP8403_RANGE_10V);

  // 设置初始输出电压
  XQ_SetDAC(GP8403_CHANNEL_BOTH, 3.1f);

  /* 编码器绑定：编码器0 → 轴0，编码器一圈10000计数，电机一圈5000脉冲 */
  // XQ_Encoder_Bindto_Axis(AXIS_0, ENCODER_AXIS_0, 400, 5000, 20 * 5000, 50000, 50000, 5, 10);

  /* 启动编码器跟随任务 */
  // XQ_Encoder_Follow_Task_Start();

  /* 输出流水跑马灯测试：OUT0~OUT48 依次点亮，每次只亮一个 */
   uint8_t chaser_pin = 0;
   const uint8_t CHASER_TOTAL = 49;  // OUT0 ~ OUT48

  // xq_line_intp (AXIS_0, AXIS_1, 5000 * 100, 5000 * 10, 0, 0, 50000, 50000, 50000, 5);

  // xq_axis_pulse_timed(AXIS_0, 1000, 5000);

  /* Infinite loop */
  for(;;) {

    /* 流水输出测试OUT0 ~ OUT48 */
			//  xqIO_Output = (1ULL << chaser_pin);
			//  chaser_pin = (chaser_pin + 1) % CHASER_TOTAL;

    /* 打印IO输入 */
    // printf("DI: 0x%02X\r\n", (unsigned int)(xqIO_Input >> 32));  // 只打印高32位的输入状态（TCA9535部分）

    /* 检查输出是否发生变化 */

    // int64_t count = XQ_Axis_Get_Encoder_Count((XQ_EncoderAxis_t)0);
    // int32_t axis0_pulse = encoder_count_to_motor_pulse(&encoder_bindings[ENCODER_AXIS_0], count);

    // printf ("Axis %d: %lld  %d  %d\r\n", 0, count, axis0_pulse, axis[AXIS_0].position);

    /* 打印所有编码器的值 */
    // for (uint8_t i = 0; i < ENCODER_AXIS_COUNT; i++) {
    //   int64_t count = XQ_Axis_Get_Encoder_Count((XQ_EncoderAxis_t)i);
    //   printf ("Axis %d: %lld  ", i, count);
    // }
    // printf ("\r\n");

    /* 编码器0的值除以10000，作为轴0的绝对位置目标（直接使用脉冲值，省去浮点运算） */
    // {
    //   int64_t enc0_count = XQ_Axis_Get_Encoder_Count(ENCODER_AXIS_0);
    //   int32_t target_pulse = (int32_t)(enc0_count / 2);

    //   if (target_pulse != axis[AXIS_0].position) {
    //     if (axis[AXIS_0].is_moving == true) {
    //       /* 运动中动态改变目标位置，先将加速度减到零再规划新轨迹 */
    //       xq_axis_change_target_position(AXIS_0, target_pulse, 20 * 5000, 50000, 50000, 5);
    //     } else {
    //       /* 静止状态，根据目标位置创建S曲线并启动 */
    //       SCurve *s = xq_axis_new_curve_for_target_position(AXIS_0, axis[AXIS_0].min_start_f, 20 * 5000, target_pulse, 50000, 50000, 5, AXIS_POS_MODE_ABS);
    //       xq_axis_start_pwm(AXIS_0, s);
    //     }
    //   }
    // }

    // if(((xqIO_Input >> 8) & 1) && !di8)
		// {
    //   printf("DI8 triggered, starting Z-axis movement\r\n");
		// 	XQ_JogMove((AxisID)0, -1, 30000, 2450, 5);//下降找平面的速度mm/s
		// }
		// di8 = (xqIO_Input >> 8) & 1;

		// if(((xqIO_Input >> 9) & 1) && !di9)
		// {
		// 	XQ_ABSMove((AxisID)0, (axis[0].position * axis[0].pitch) / axis[0].microsteps, 1.5, 30000, 2450, 5);
		// }
		// di9 = (xqIO_Input >> 9) & 1;

    // PWM测试：每隔200ms改变一次占空比，实现渐变效果
    // if (osKernelGetTickCount() - pwm_tick >= 100) {
    //   pwm_tick = osKernelGetTickCount();

    //   // 更新占空比
    //   pwm_duty += pwm_direction * 0.05f;

    //   // 检查边界并反转方向
    //   if (pwm_duty >= 0.9f) {
    //     pwm_duty = 0.9f;
    //     pwm_direction = -1;  // 开始递减
    //   } else if (pwm_duty <= 0.1f) {
    //     pwm_duty = 0.1f;
    //     pwm_direction = 1;   // 开始递增
    //   }

    //   // 设置PWM占空比（周期500μs，间歇发送2个周期后停止1000μs）
    //   XQ_setPWM(0, pwm_duty, 500.0, 2, 1000);
    //   XQ_setPWM(1, pwm_duty, 500.0, 2, 1000);
    // }

    // 获取交叉采样的ADC数据（ADC1+ADC2双模式）

    // if (status == HAL_OK) {
    //   for (int i = 0; i < 200; i++) {
    //     printf ("%.3f ", adc_voltage[i]);
    //   }
    //   printf("\r\n");
    // }

    // uint32_t ti = t2t1;
    // printf ("t2t1 = %d\n", ti);
    // printf ("MSPS = %.2f\n", 1.0/((double_t)ti/500.0)); // 计算采样率

    /* 打印pwm1_level */
    // for (uint32_t i = 0; i < 1000; i++)
    // {
    //   printf ("%0.3f ", adc_voltage[i]);
    // }

    // printf ("\r\n");
    // printf ("t2t1 = %d\n", t2t1);

// XQ_ABSMove((AxisID)0, 1, 5, 30000, 2450, 5);
// osDelay(3000);
// XQ_ABSMove((AxisID)0, 5, 5, 30000, 2450, 5);
// osDelay(3000);
// XQ_ABSMove((AxisID)0, 10, 5, 30000, 2450, 5);
// osDelay(100);
// XQ_ABSMove((AxisID)0, 1, 5, 30000, 2450, 5);
// osDelay(100);

    HAL_GPIO_TogglePin (SYS_RUN_GPIO_Port, SYS_RUN_Pin);
    osDelay(1000);
  }
  /* USER CODE END StartDefaultTask */
}
